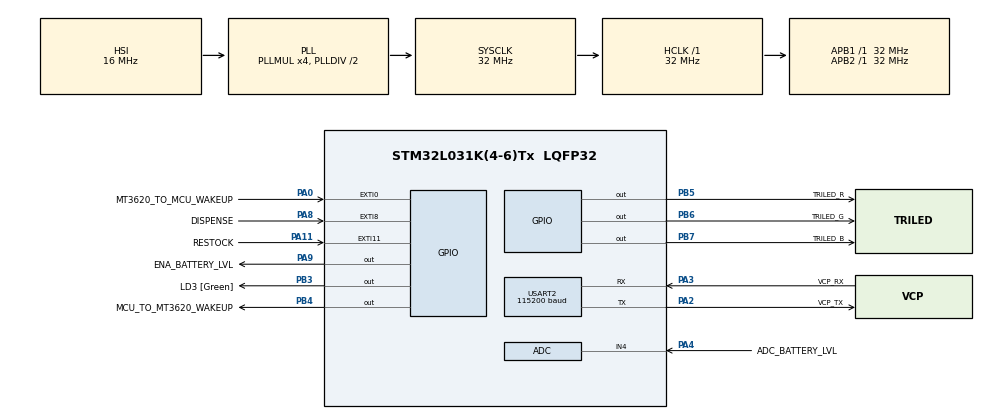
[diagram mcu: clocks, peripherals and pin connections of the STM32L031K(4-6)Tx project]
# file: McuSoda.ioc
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ADC.ContinuousConvMode=ENABLE
ADC.SamplingTime=ADC_SAMPLETIME_7CYCLES_5
Mcu.Family=STM32L0
Mcu.Name=STM32L031K(4-6)Tx
Mcu.Package=LQFP32
NVIC.EXTI0_1_IRQn=true\:0\:0\:false\:false\:true\:true\:true
NVIC.EXTI4_15_IRQn=true\:0\:0\:false\:false\:true\:true\:true
NVIC.USART2_IRQn=true\:0\:0\:false\:false\:true\:true\:true
PA0-CK_IN.GPIO_Label=MT3620_TO_MCU_WAKEUP
PA0-CK_IN.GPIO_ModeDefaultEXTI=GPIO_MODE_IT_FALLING
PA0-CK_IN.GPIO_PuPd=GPIO_PULLUP
PA0-CK_IN.Signal=GPXTI0
PA11.GPIO_Label=RESTOCK
PA11.GPIO_ModeDefaultEXTI=GPIO_MODE_IT_FALLING
PA11.Signal=GPXTI11
PA13.GPIO_Label=TMS
PA13.Signal=SYS_SWDIO
PA14.GPIO_Label=TCK
PA14.Signal=SYS_SWCLK
PA2.GPIO_Label=VCP_TX
PA2.Mode=Asynchronous
PA2.Signal=USART2_TX
PA3.GPIO_Label=VCP_RX
PA3.Mode=Asynchronous
PA3.Signal=USART2_RX
PA4.GPIO_Label=ADC_BATTERY_LVL
PA4.Mode=IN4
PA4.Signal=ADC_IN4
PA8.GPIO_Label=DISPENSE
PA8.GPIO_ModeDefaultEXTI=GPIO_MODE_IT_FALLING
PA8.GPIO_PuPd=GPIO_NOPULL
PA8.Signal=GPXTI8
PA9.GPIO_Label=ENA_BATTERY_LVL
PA9.Signal=GPIO_Output
PB3.GPIO_Label=LD3 [Green]
PB3.Signal=GPIO_Output
PB4.GPIO_Label=MCU_TO_MT3620_WAKEUP
PB4.GPIO_ModeDefaultOutputPP=GPIO_MODE_OUTPUT_OD
PB4.GPIO_PuPd=GPIO_NOPULL
PB4.PinState=GPIO_PIN_SET
PB4.Signal=GPIO_Output
PB5.GPIO_Label=TRILED_R
PB5.Signal=GPIO_Output
PB6.GPIO_Label=TRILED_G
PB6.Signal=GPIO_Output
PB7.GPIO_Label=TRILED_B
PB7.Signal=GPIO_Output
PC14-OSC32_IN.Signal=RCC_OSC32_IN
PC15-OSC32_OUT.Signal=RCC_OSC32_OUT
ProjectManager.HeapSize=0x200
ProjectManager.StackSize=0x400
ProjectManager.TargetToolchain=STM32CubeIDE
RCC.AHBFreq_Value=32000000
RCC.APB1Freq_Value=32000000
RCC.APB1TimFreq_Value=32000000
RCC.APB2Freq_Value=32000000
RCC.APB2TimFreq_Value=32000000
RCC.HCLKFreq_Value=32000000
RCC.HSE_VALUE=8000000
RCC.HSI16_VALUE=16000000
RCC.HSI48_VALUE=48000000
RCC.HSI_VALUE=16000000
RCC.LSE_VALUE=32768
RCC.MSI_VALUE=2097000
RCC.PLLMUL=RCC_PLLMUL_4
RCC.SYSCLKFreq_VALUE=32000000
RCC.SYSCLKSource=RCC_SYSCLKSOURCE_PLLCLK
RCC.VCOOutputFreq_Value=64000000
USART2.BaudRate=115200
USART2.VirtualMode-Asynchronous=VM_ASYNC
board=NUCLEO-L031K6

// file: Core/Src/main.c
/* USER CODE BEGIN Header */
/* Portions copyright Microsoft. */
/**
  ******************************************************************************
  * @file           : main.c
  * @brief          : Main program body
  ******************************************************************************
  * @attention
  *
  * <h2><center>&copy; Copyright (c) 2020 STMicroelectronics.
  * All rights reserved.</center></h2>
  *
  * This software component is licensed by ST under BSD 3-Clause license,
  * the "License"; You may not use this file except in compliance with the
  * License. You may obtain a copy of the License at:
  *                        opensource.org/licenses/BSD-3-Clause
  *
  ******************************************************************************
  */
/* USER CODE END Header */

#include "main.h"

ADC_HandleTypeDef hadc;

UART_HandleTypeDef huart2;

void SystemClock_Config(void);
static void MX_GPIO_Init(void);
static void MX_USART2_UART_Init(void);
static void MX_ADC_Init(void);

int main(void)
{

  /* MCU Configuration--------------------------------------------------------*/

  /* Reset of all peripherals, Initializes the Flash interface and the Systick. */
  HAL_Init();

  /* Configure the system clock */
  SystemClock_Config();

  /* Initialize all configured peripherals */
  MX_GPIO_Init();
  MX_USART2_UART_Init();
  MX_ADC_Init();
  /* USER CODE BEGIN 2 */
  RunSodaMachine();
  /* USER CODE END 2 */

  /* Infinite loop */
  while (1)
  {

  }
}

void SystemClock_Config(void)
{
  RCC_OscInitTypeDef RCC_OscInitStruct = {0};
  RCC_ClkInitTypeDef RCC_ClkInitStruct = {0};
  RCC_PeriphCLKInitTypeDef PeriphClkInit = {0};

  /** Configure the main internal regulator output voltage
  */
  __HAL_PWR_VOLTAGESCALING_CONFIG(PWR_REGULATOR_VOLTAGE_SCALE1);
  /** Initializes the CPU, AHB and APB busses clocks
  */
  RCC_OscInitStruct.OscillatorType = RCC_OSCILLATORTYPE_HSI;
  RCC_OscInitStruct.HSIState = RCC_HSI_ON;
  RCC_OscInitStruct.HSICalibrationValue = RCC_HSICALIBRATION_DEFAULT;
  RCC_OscInitStruct.PLL.PLLState = RCC_PLL_ON;
  RCC_OscInitStruct.PLL.PLLSource = RCC_PLLSOURCE_HSI;
  RCC_OscInitStruct.PLL.PLLMUL = RCC_PLLMUL_4;
  RCC_OscInitStruct.PLL.PLLDIV = RCC_PLLDIV_2;
  if (HAL_RCC_OscConfig(&RCC_OscInitStruct) != HAL_OK)
  {
    Error_Handler();
  }
  /** Initializes the CPU, AHB and APB busses clocks
  */
  RCC_ClkInitStruct.ClockType = RCC_CLOCKTYPE_HCLK|RCC_CLOCKTYPE_SYSCLK
                              |RCC_CLOCKTYPE_PCLK1|RCC_CLOCKTYPE_PCLK2;
  RCC_ClkInitStruct.SYSCLKSource = RCC_SYSCLKSOURCE_PLLCLK;
  RCC_ClkInitStruct.AHBCLKDivider = RCC_SYSCLK_DIV1;
  RCC_ClkInitStruct.APB1CLKDivider = RCC_HCLK_DIV1;
  RCC_ClkInitStruct.APB2CLKDivider = RCC_HCLK_DIV1;

  if (HAL_RCC_ClockConfig(&RCC_ClkInitStruct, FLASH_LATENCY_1) != HAL_OK)
  {
    Error_Handler();
  }
  PeriphClkInit.PeriphClockSelection = RCC_PERIPHCLK_USART2;
  PeriphClkInit.Usart2ClockSelection = RCC_USART2CLKSOURCE_PCLK1;
  if (HAL_RCCEx_PeriphCLKConfig(&PeriphClkInit) != HAL_OK)
  {
    Error_Handler();
  }
}

static void MX_ADC_Init(void)
{

  ADC_ChannelConfTypeDef sConfig = {0};

  /** Configure the global features of the ADC (Clock, Resolution, Data Alignment and number of conversion)
  */
  hadc.Instance = ADC1;
  hadc.Init.OversamplingMode = DISABLE;
  hadc.Init.ClockPrescaler = ADC_CLOCK_SYNC_PCLK_DIV2;
  hadc.Init.Resolution = ADC_RESOLUTION_12B;
  hadc.Init.SamplingTime = ADC_SAMPLETIME_7CYCLES_5;
  hadc.Init.ScanConvMode = ADC_SCAN_DIRECTION_FORWARD;
  hadc.Init.DataAlign = ADC_DATAALIGN_RIGHT;
  hadc.Init.ContinuousConvMode = ENABLE;
  hadc.Init.DiscontinuousConvMode = DISABLE;
  hadc.Init.ExternalTrigConvEdge = ADC_EXTERNALTRIGCONVEDGE_NONE;
  hadc.Init.ExternalTrigConv = ADC_SOFTWARE_START;
  hadc.Init.DMAContinuousRequests = DISABLE;
  hadc.Init.EOCSelection = ADC_EOC_SINGLE_CONV;
  hadc.Init.Overrun = ADC_OVR_DATA_PRESERVED;
  hadc.Init.LowPowerAutoWait = DISABLE;
  hadc.Init.LowPowerFrequencyMode = DISABLE;
  hadc.Init.LowPowerAutoPowerOff = DISABLE;
  if (HAL_ADC_Init(&hadc) != HAL_OK)
  {
    Error_Handler();
  }
  /** Configure for the selected ADC regular channel to be converted.
  */
  sConfig.Channel = ADC_CHANNEL_4;
  sConfig.Rank = ADC_RANK_CHANNEL_NUMBER;
  if (HAL_ADC_ConfigChannel(&hadc, &sConfig) != HAL_OK)
  {
    Error_Handler();
  }

}

static void MX_USART2_UART_Init(void)
{

  huart2.Instance = USART2;
  huart2.Init.BaudRate = 115200;
  huart2.Init.WordLength = UART_WORDLENGTH_8B;
  huart2.Init.StopBits = UART_STOPBITS_1;
  huart2.Init.Parity = UART_PARITY_NONE;
  huart2.Init.Mode = UART_MODE_TX_RX;
  huart2.Init.HwFlowCtl = UART_HWCONTROL_NONE;
  huart2.Init.OverSampling = UART_OVERSAMPLING_16;
  huart2.Init.OneBitSampling = UART_ONE_BIT_SAMPLE_DISABLE;
  huart2.AdvancedInit.AdvFeatureInit = UART_ADVFEATURE_NO_INIT;
  if (HAL_UART_Init(&huart2) != HAL_OK)
  {
    Error_Handler();
  }

}

static void MX_GPIO_Init(void)
{
  GPIO_InitTypeDef GPIO_InitStruct = {0};

  /* GPIO Ports Clock Enable */
  __HAL_RCC_GPIOC_CLK_ENABLE();
  __HAL_RCC_GPIOA_CLK_ENABLE();
  __HAL_RCC_GPIOB_CLK_ENABLE();

  /*Configure GPIO pin Output Level */
  HAL_GPIO_WritePin(ENA_BATTERY_LVL_GPIO_Port, ENA_BATTERY_LVL_Pin, GPIO_PIN_RESET);

  /*Configure GPIO pin Output Level */
  HAL_GPIO_WritePin(GPIOB, LD3_Pin|TRILED_R_Pin|TRILED_G_Pin|TRILED_B_Pin, GPIO_PIN_RESET);

  /*Configure GPIO pin Output Level */
  HAL_GPIO_WritePin(MCU_TO_MT3620_WAKEUP_GPIO_Port, MCU_TO_MT3620_WAKEUP_Pin, GPIO_PIN_SET);

  /*Configure GPIO pin : MT3620_TO_MCU_WAKEUP_Pin */
  GPIO_InitStruct.Pin = MT3620_TO_MCU_WAKEUP_Pin;
  GPIO_InitStruct.Mode = GPIO_MODE_IT_FALLING;
  GPIO_InitStruct.Pull = GPIO_PULLUP;
  HAL_GPIO_Init(MT3620_TO_MCU_WAKEUP_GPIO_Port, &GPIO_InitStruct);

  /*Configure GPIO pins : DISPENSE_Pin RESTOCK_Pin */
  GPIO_InitStruct.Pin = DISPENSE_Pin|RESTOCK_Pin;
  GPIO_InitStruct.Mode = GPIO_MODE_IT_FALLING;
  GPIO_InitStruct.Pull = GPIO_NOPULL;
  HAL_GPIO_Init(GPIOA, &GPIO_InitStruct);

  /*Configure GPIO pin : ENA_BATTERY_LVL_Pin */
  GPIO_InitStruct.Pin = ENA_BATTERY_LVL_Pin;
  GPIO_InitStruct.Mode = GPIO_MODE_OUTPUT_PP;
  GPIO_InitStruct.Pull = GPIO_NOPULL;
  GPIO_InitStruct.Speed = GPIO_SPEED_FREQ_LOW;
  HAL_GPIO_Init(ENA_BATTERY_LVL_GPIO_Port, &GPIO_InitStruct);

  /*Configure GPIO pins : LD3_Pin TRILED_R_Pin TRILED_G_Pin TRILED_B_Pin */
  GPIO_InitStruct.Pin = LD3_Pin|TRILED_R_Pin|TRILED_G_Pin|TRILED_B_Pin;
  GPIO_InitStruct.Mode = GPIO_MODE_OUTPUT_PP;
  GPIO_InitStruct.Pull = GPIO_NOPULL;
  GPIO_InitStruct.Speed = GPIO_SPEED_FREQ_LOW;
  HAL_GPIO_Init(GPIOB, &GPIO_InitStruct);

  /*Configure GPIO pin : MCU_TO_MT3620_WAKEUP_Pin */
  GPIO_InitStruct.Pin = MCU_TO_MT3620_WAKEUP_Pin;
  GPIO_InitStruct.Mode = GPIO_MODE_OUTPUT_OD;
  GPIO_InitStruct.Pull = GPIO_NOPULL;
  GPIO_InitStruct.Speed = GPIO_SPEED_FREQ_LOW;
  HAL_GPIO_Init(MCU_TO_MT3620_WAKEUP_GPIO_Port, &GPIO_InitStruct);

  /* EXTI interrupt init*/
  HAL_NVIC_SetPriority(EXTI0_1_IRQn, 0, 0);
  HAL_NVIC_EnableIRQ(EXTI0_1_IRQn);

  HAL_NVIC_SetPriority(EXTI4_15_IRQn, 0, 0);
  HAL_NVIC_EnableIRQ(EXTI4_15_IRQn);

}

_Noreturn void Error_Handler(void)
{
  /* USER CODE BEGIN Error_Handler_Debug */
  /* User can add his own implementation to report the HAL error return state */

	// Switch on LED and spin, to tell user something is wrong.
	HAL_GPIO_WritePin(LD3_GPIO_Port, LD3_Pin, GPIO_PIN_SET);
	for (;;) {
		// empty.
	}
  /* USER CODE END Error_Handler_Debug */
}

/************************ (C) COPYRIGHT STMicroelectronics *****END OF FILE****/
